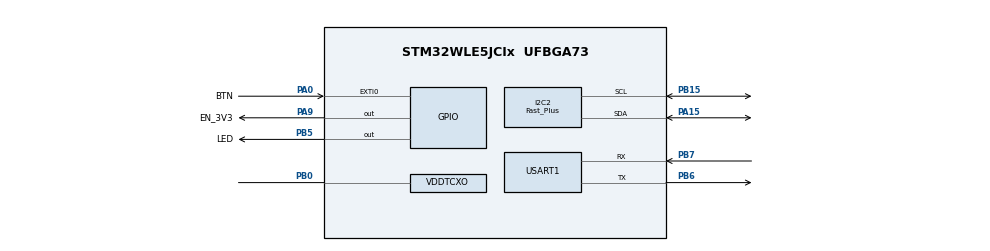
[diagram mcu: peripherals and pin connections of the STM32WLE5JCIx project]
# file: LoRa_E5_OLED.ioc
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Mcu.Family=STM32WL
PC15-OSC32_OUT.Mode=LSE-External-Oscillator
RCC.CortexFreq_Value=48000000
PA9.GPIO_Label=EN_3V3
I2C2.Timing=0x20000209
PA0.GPIO_Label=BTN
PC14-OSC32_IN.Signal=RCC_OSC32_IN
PB15.Signal=I2C2_SCL
ProjectManager.StackSize=0x400
USART1.VirtualMode-Asynchronous=VM_ASYNC
ProjectManager.TargetToolchain=STM32CubeIDE
PB0-VDD_TCXO.Mode=HSE-TCXO
RCC.HCLKFreq_Value=48000000
I2C2.I2C_Speed_Mode=I2C_Fast_Plus
RCC.APB2TimFreq_Value=48000000
PA9.Signal=GPIO_Output
PB6.Signal=USART1_TX
PB6.Mode=Asynchronous
OSC_IN.Signal=RCC_OSC_IN
RCC.LSE_VALUE=32768
PC15-OSC32_OUT.Signal=RCC_OSC32_OUT
RCC.AHBFreq_Value=48000000
RCC.HSE_VALUE=8000000
board=custom
RCC.VCOOutputFreq_Value=384000000
PA15.Mode=I2C
PB15.Mode=I2C
RCC.APB2Freq_Value=48000000
PC14-OSC32_IN.Mode=LSE-External-Oscillator
PB7.Signal=USART1_RX
PB0-VDD_TCXO.Signal=VDDTCXO
Mcu.Name=STM32WLE5JCIx
PA0.Signal=GPXTI0
RCC.APB3Freq_Value=48000000
NVIC.EXTI0_IRQn=true\:0\:0\:false\:false\:true\:true\:true
RCC.SYSCLKFreq_VALUE=48000000
PB5.Signal=GPIO_Output
Mcu.Package=UFBGA73
OSC_IN.Mode=HSE-TCXO
PA0.GPIO_PuPd=GPIO_PULLUP
PB7.Mode=Asynchronous
PA15.Signal=I2C2_SDA
ProjectManager.HeapSize=0x200
RCC.HSI_VALUE=16000000
NVIC.PriorityGroup=NVIC_PRIORITYGROUP_4
PB5.GPIO_Label=LED
RCC.APB1TimFreq_Value=48000000
RCC.APB1Freq_Value=48000000
RCC.MSIClockRange=RCC_MSIRANGE_11

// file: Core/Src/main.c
/* USER CODE BEGIN Header */
/**
  ******************************************************************************
  * @file           : main.c
  * @brief          : Main program body
  ******************************************************************************
  * @attention
  *
  * <h2><center>&copy; Copyright (c) 2021 STMicroelectronics.
  * All rights reserved.</center></h2>
  *
  * This software component is licensed by ST under BSD 3-Clause license,
  * the "License"; You may not use this file except in compliance with the
  * License. You may obtain a copy of the License at:
  *                        opensource.org/licenses/BSD-3-Clause
  *
  ******************************************************************************
  */
/* USER CODE END Header */
#include "main.h"
#include "i2c.h"
#include "usart.h"
#include "gpio.h"

/* USER CODE BEGIN Includes */
#include "ssd1306_conf.h"
#include "ssd1306.h"
#include "ssd1306_tests.h"
/* USER CODE END Includes */

/* USER CODE BEGIN PV */
int i=0;
/* USER CODE END PV */

void SystemClock_Config(void);
/* USER CODE BEGIN PFP */
void HAL_GPIO_EXTI_Callback(uint16_t GPIO_Pin);
/* USER CODE END PFP */

int main(void)
{

  /* MCU Configuration--------------------------------------------------------*/

  /* Reset of all peripherals, Initializes the Flash interface and the Systick. */
  HAL_Init();

  /* Configure the system clock */
  SystemClock_Config();

  /* Initialize all configured peripherals */
  MX_GPIO_Init();
  MX_I2C2_Init();
  MX_USART1_UART_Init();
  /* USER CODE BEGIN 2 */

  //Enable 3V3 For OLED
   HAL_GPIO_WritePin(EN_3V3_GPIO_Port, EN_3V3_Pin, GPIO_PIN_SET);
   HAL_Delay(500);

   ssd1306_Init();
  /* USER CODE END 2 */

  /* Infinite loop */
  /* USER CODE BEGIN WHILE */
  while (1)
  {
	  ssd1306_TestAll();
    /* USER CODE END WHILE */

  }
}

void SystemClock_Config(void)
{
  RCC_OscInitTypeDef RCC_OscInitStruct = {0};
  RCC_ClkInitTypeDef RCC_ClkInitStruct = {0};

  /** Configure LSE Drive Capability
  */
  HAL_PWR_EnableBkUpAccess();
  __HAL_RCC_LSEDRIVE_CONFIG(RCC_LSEDRIVE_LOW);
  /** Configure the main internal regulator output voltage
  */
  __HAL_PWR_VOLTAGESCALING_CONFIG(PWR_REGULATOR_VOLTAGE_SCALE1);
  /** Initializes the CPU, AHB and APB busses clocks
  */
  RCC_OscInitStruct.OscillatorType = RCC_OSCILLATORTYPE_LSE|RCC_OSCILLATORTYPE_MSI;
  RCC_OscInitStruct.LSEState = RCC_LSE_ON;
  RCC_OscInitStruct.MSIState = RCC_MSI_ON;
  RCC_OscInitStruct.MSICalibrationValue = RCC_MSICALIBRATION_DEFAULT;
  RCC_OscInitStruct.MSIClockRange = RCC_MSIRANGE_11;
  RCC_OscInitStruct.PLL.PLLState = RCC_PLL_NONE;
  if (HAL_RCC_OscConfig(&RCC_OscInitStruct) != HAL_OK)
  {
    Error_Handler();
  }
  /** Configure the SYSCLKSource, HCLK, PCLK1 and PCLK2 clocks dividers
  */
  RCC_ClkInitStruct.ClockType = RCC_CLOCKTYPE_HCLK3|RCC_CLOCKTYPE_HCLK
                              |RCC_CLOCKTYPE_SYSCLK|RCC_CLOCKTYPE_PCLK1
                              |RCC_CLOCKTYPE_PCLK2;
  RCC_ClkInitStruct.SYSCLKSource = RCC_SYSCLKSOURCE_MSI;
  RCC_ClkInitStruct.AHBCLKDivider = RCC_SYSCLK_DIV1;
  RCC_ClkInitStruct.APB1CLKDivider = RCC_HCLK_DIV1;
  RCC_ClkInitStruct.APB2CLKDivider = RCC_HCLK_DIV1;
  RCC_ClkInitStruct.AHBCLK3Divider = RCC_SYSCLK_DIV1;

  if (HAL_RCC_ClockConfig(&RCC_ClkInitStruct, FLASH_LATENCY_2) != HAL_OK)
  {
    Error_Handler();
  }
}

/* USER CODE BEGIN 4 */
void HAL_GPIO_EXTI_Callback(uint16_t GPIO_Pin){
	if(GPIO_Pin == BTN_Pin){
		ssd1306_Fill(Black);
	}
}
/* USER CODE END 4 */

void Error_Handler(void)
{
  __disable_irq();
  while (1)
  {
  }
}

/************************ (C) COPYRIGHT STMicroelectronics *****END OF FILE****/
